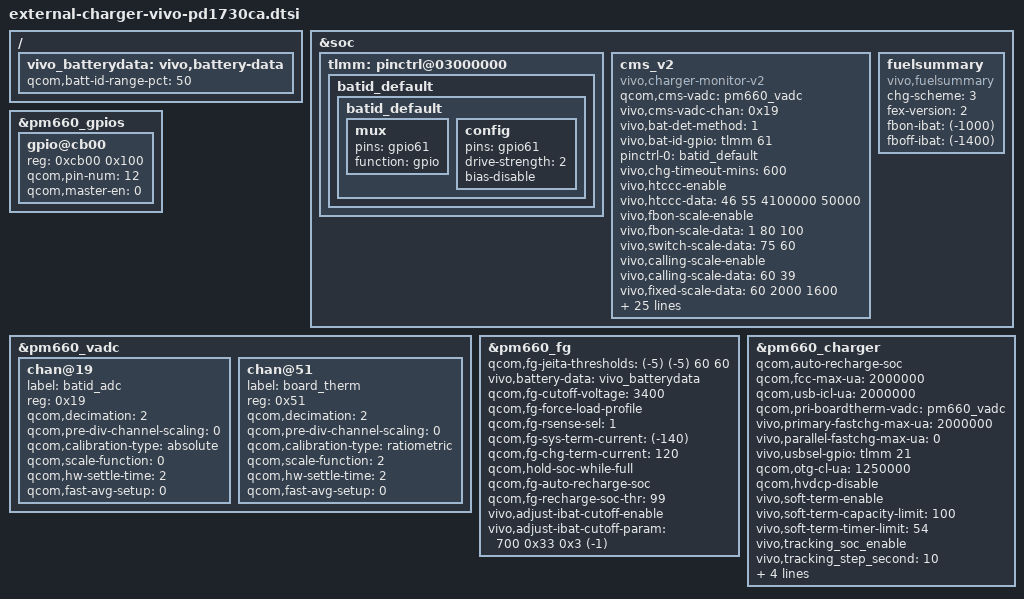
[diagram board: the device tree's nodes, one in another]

&soc {
	tlmm: pinctrl@03000000 {
		batid_default{
			batid_default: batid_default {
				mux {
					pins = "gpio61";
					function = "gpio";
				};
				config {
					pins = "gpio61";
					drive-strength = <2>;
					bias-disable;
				};
			};
		};
	};
};

&pm660_gpios{
	gpio@cb00 {
		reg = <0xcb00 0x100>;
		qcom,pin-num = <12>;
		status = "ok";
		//qcom,mode = <3>; //ANA_PASS_THRU
		qcom,master-en = <0>; /* enable GPIO */
	};
};

&pm660_vadc{
	chan@19 {
		label = "batid_adc";
		reg = <0x19>; // channel for GPIO12
		qcom,decimation = <2>;
		qcom,pre-div-channel-scaling = <0>; //1:1 scaling
		qcom,calibration-type = "absolute";
		qcom,scale-function = <0>; // this should be 0, not 2
		qcom,hw-settle-time = <2>;
		qcom,fast-avg-setup = <0>;
	};

	chan@51 {
		label = "board_therm";
		reg = <0x51>;
		qcom,decimation = <2>;
		qcom,pre-div-channel-scaling = <0>;
		qcom,calibration-type = "ratiometric";
		qcom,scale-function = <2>;
		qcom,hw-settle-time = <2>;
		qcom,fast-avg-setup = <0>;
	};
};

/ {
	vivo_batterydata: vivo,battery-data {
		qcom,batt-id-range-pct = <50>;
		#include "fg-gen3-batterydata-pd1730ca-3180mah.dtsi"
	};
};

&pm660_fg {
	qcom,fg-jeita-thresholds = <(-5) (-5) 60 60>;
	vivo,battery-data = <&vivo_batterydata>;
	qcom,fg-cutoff-voltage = <3400>;
	qcom,fg-force-load-profile;
	qcom,fg-rsense-sel = <1>;//external R read current
	qcom,fg-sys-term-current = <(-140)>;
	qcom,fg-chg-term-current = <120>;
	qcom,hold-soc-while-full;
	qcom,fg-auto-recharge-soc;
	qcom,fg-recharge-soc-thr = <99>;
	//qcom,fg-recharge-voltage = <4250>;

	/* ibat cutoff calculation algorithm: */
	/* val = ibat_cutoff / 0.00012207 */
	/* 100mA: val = 0.1/0.00012207 = 0x333 */
	/* 200mA: val = 0.2/0.00012207 = 0x666 */
	/* 300mA: val = 0.3/0.00012207 = 0x999 */
	/* 400mA: val = 0.4/0.00012207 = 0xCCC */
	/* param: <temperature bit0 bit1 batid>,when batid=-1,all batt must ajust */
	vivo,adjust-ibat-cutoff-enable;
	vivo,adjust-ibat-cutoff-param = <700 0x33 0x3 (-1)>;
};


&pm660_charger {
	qcom,auto-recharge-soc;
	qcom,fcc-max-ua = <2000000>;
	qcom,usb-icl-ua = <2000000>;
	qcom,pri-boardtherm-vadc = <&pm660_vadc>;
	vivo,primary-fastchg-max-ua = <2000000>;
	vivo,parallel-fastchg-max-ua = <0>;
	vivo,usbsel-gpio = <&tlmm 21 0>;
	//vivo,usboe-gpio = <&tlmm 21 0>;
	qcom,otg-cl-ua = <1250000>;

	qcom,hvdcp-disable;

	vivo,soft-term-enable;
	vivo,soft-term-capacity-limit = <100>;
	vivo,soft-term-timer-limit = <54>;//9min

	vivo,tracking_soc_enable;
	vivo,tracking_step_second= <10>;

	/*charge condition force 5v*/
	vivo,cc-force-5v-soc-limit = <90>;

	vivo,current_spec_min_ma = <1000>;	// = vivo,primary-fastchg-max-ua + vivo,parallel-fastchg-max-ua - 1000
	vivo,current_spec_max_ma = <2100>;	// = vivo,primary-fastchg-max-ua + vivo,parallel-fastchg-max-ua + 100

	/*
	enum SUPPORTED_ADAPTER {
		SUPPORTED_ADAPTER_DEFAULT = 0
		SUPPORTED_ADAPTER_VIVO_LV_DCHG__5V_4500MA = 1,
		SUPPORTED_ADAPTER_VIVO_HV_DCHG__10V_2250MA = 2,
		SUPPORTED_ADAPTER_QC20__9V_2000MA = 3,
	};
	*/
	vivo,supported-adapter = <0>;
};


&soc {
	cms_v2 {
		compatible = "vivo,charger-monitor-v2";

		//vivo,battery-plugable = <0>;//0:unplugable,1:plugable , default:0
		qcom,cms-vadc = <&pm660_vadc>;//when use ex-fg or eprom,this prop will delete
		vivo,cms-vadc-chan = <0x19>;
		vivo,bat-det-method = <1>;  //r:0 , rc:1 , eprom:2, ex-fg:3
		vivo,bat-id-gpio = <&tlmm 61 0>;
		pinctrl-names = "default";
		pinctrl-0 = <&batid_default>;

		//vivo,no-bat-warning;
		//vivo,no-chg-timeout;
		vivo,chg-timeout-mins = <600>;

		//high temperature charger current control enable
		vivo,htccc-enable;
		vivo,htccc-data = <46 55 4100000 50000>;

		vivo,fbon-scale-enable;
		vivo,fbon-scale-data = <1 80 100>;

		//vivo,switch-scale-enable;
		vivo,switch-scale-data = <75 60>;

		vivo,calling-scale-enable;
		vivo,calling-scale-data = <60 39>;

		//vivo,fixed-scale-enable;
		vivo,fixed-scale-data = <60 2000 1600>;

		//battery voltage compensate
		vivo,vbat-r-comp = <20>;

		/* usb connecter protect param */
		//vivo,usb-connecter-protect-enable;
		vivo,usb-id-protect-data= <1100 1547 500>;/* 500K, 2M, fcc */
		vivo,usb-conn-heat-protect-data= <800 550>;

		//ibat scale base on temperature
		vivo,normal-tc-row-col = <7 5>;
		vivo,normal-tc-data = <550 8888 0 0 0>,	//0.7c
					<450 549 50 0 0>,
					<150 449 70 0 0>,
					<100 149 70 4200000 50>,
					<50 99 30 0 0>,
					<0 49 20 0 0>,
					<(-8888) (-1) 0 0 0>;

		//adjust fastchg base on board temperature and fb off
		vivo,intell-charge-enable;
		vivo,parallel-temp-enable = <1 1>;//<x y> x:fb-on y:fb-off
		//fb-on param
		vivo,primary-fbon-tc-row-col = <5 3>;
		vivo,primary-fbon-tc-data = <471 8888 500>,
					    <411 470 950>,
					    <381 410 1000>,
					    <351 380 1200>,
					    <(-8888) 350 1600>;
		vivo,parallel-fbon-tc-row-col = <4 3>;
		vivo,parallel-fbon-tc-data = <441 8888 0>,
					     <411 440 0>,
					     <371 410 0>,
					     <(-8888) 370 0>;
		//fb-off param
		vivo,primary-fboff-tc-row-col = <6 3>;
		vivo,primary-fboff-tc-data = <451 8888 500>,
					     <401 450 1000>,
					     <391 400 1200>,
					     <351 390 1600>,
					     <331 350 1800>,
					     <(-8888) 330 2000>;
		vivo,parallel-fboff-tc-row-col = <5 3>;
		vivo,parallel-fboff-tc-data = <401 8888 0>,
					      <381 400 0>,
					      <351 380 0>,
					      <301 350 0>,
					      <(-8888) 300 0>;
	};

	fuelsummary {
		compatible = "vivo,fuelsummary";

		/************************************************************
		 *
		 *  0	vivo-fastchg
		 *  1	qcom-dualchg
		 *  2	mtk-dualchg
		 *  3	qcom-normchg
		 *  4	mtk-normchg
		 *
		 ***********************************************************/
		chg-scheme = <3>;
		fex-version = <2>;
		fbon-ibat = <(-1000)>;
		fboff-ibat = <(-1400)>;
	};
};
